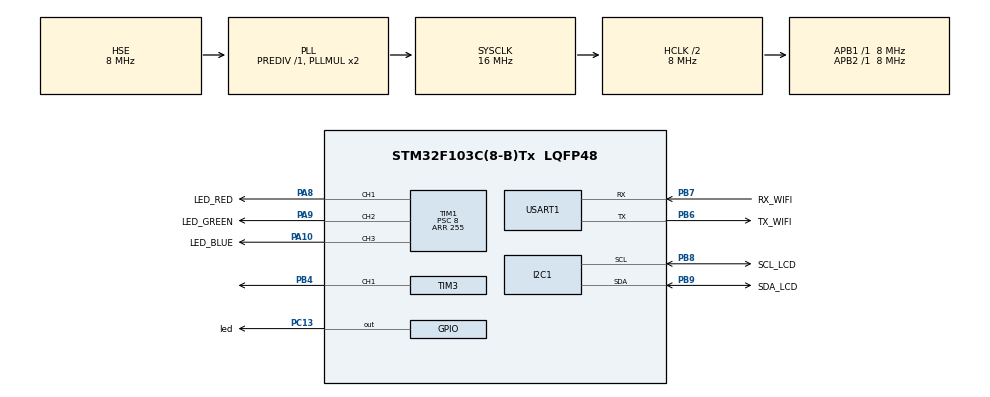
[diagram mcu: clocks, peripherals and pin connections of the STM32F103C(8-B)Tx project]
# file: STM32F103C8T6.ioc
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Mcu.Family=STM32F1
Mcu.Name=STM32F103C(8-B)Tx
Mcu.Package=LQFP48
NVIC.PriorityGroup=NVIC_PRIORITYGROUP_4
NVIC.TIM2_IRQn=true\:0\:0\:false\:false\:true\:true\:true
NVIC.USART1_IRQn=true\:0\:0\:false\:false\:true\:true\:true
PA10.GPIO_Label=LED_BLUE
PA10.Signal=S_TIM1_CH3
PA13.Mode=Serial_Wire
PA13.Signal=SYS_JTMS-SWDIO
PA14.Mode=Serial_Wire
PA14.Signal=SYS_JTCK-SWCLK
PA8.GPIO_Label=LED_RED
PA8.Signal=S_TIM1_CH1
PA9.GPIO_Label=LED_GREEN
PA9.Signal=S_TIM1_CH2
PB4.Signal=S_TIM3_CH1
PB6.GPIO_Label=TX_WIFI
PB6.Mode=Asynchronous
PB6.Signal=USART1_TX
PB7.GPIO_Label=RX_WIFI
PB7.Mode=Asynchronous
PB7.Signal=USART1_RX
PB8.GPIO_Label=SCL_LCD
PB8.Mode=I2C
PB8.Signal=I2C1_SCL
PB9.GPIO_Label=SDA_LCD
PB9.Mode=I2C
PB9.Signal=I2C1_SDA
PC13-TAMPER-RTC.GPIO_Label=led
PC13-TAMPER-RTC.Signal=GPIO_Output
PD0-OSC_IN.Mode=HSE-External-Oscillator
PD0-OSC_IN.Signal=RCC_OSC_IN
PD1-OSC_OUT.Mode=HSE-External-Oscillator
PD1-OSC_OUT.Signal=RCC_OSC_OUT
ProjectManager.HeapSize=0x200
ProjectManager.StackSize=0x400
ProjectManager.TargetToolchain=STM32CubeIDE
RCC.AHBCLKDivider=RCC_SYSCLK_DIV2
RCC.AHBFreq_Value=8000000
RCC.APB1Freq_Value=8000000
RCC.APB1TimFreq_Value=8000000
RCC.APB2Freq_Value=8000000
RCC.APB2TimFreq_Value=8000000
RCC.HCLKFreq_Value=8000000
RCC.PLLSourceVirtual=RCC_PLLSOURCE_HSE
RCC.SYSCLKFreq_VALUE=16000000
RCC.SYSCLKSource=RCC_SYSCLKSOURCE_PLLCLK
RCC.USBFreq_Value=16000000
SH.S_TIM1_CH1.0=TIM1_CH1,PWM Generation1 CH1
SH.S_TIM1_CH2.0=TIM1_CH2,PWM Generation2 CH2
SH.S_TIM1_CH3.0=TIM1_CH3,PWM Generation3 CH3
SH.S_TIM3_CH1.0=TIM3_CH1,PWM Generation1 CH1
TIM1.AutoReloadPreload=TIM_AUTORELOAD_PRELOAD_ENABLE
TIM1.Channel-PWM\ Generation1\ CH1=TIM_CHANNEL_1
TIM1.Channel-PWM\ Generation2\ CH2=TIM_CHANNEL_2
TIM1.Channel-PWM\ Generation3\ CH3=TIM_CHANNEL_3
TIM1.Period=255
TIM1.Prescaler=8
TIM2.Period=9
TIM2.Prescaler=7999
TIM3.Channel-PWM\ Generation1\ CH1=TIM_CHANNEL_1
TIM3.Period=1000
TIM3.Pulse-PWM\ Generation1\ CH1=500
USART1.VirtualMode=VM_ASYNC
VP_TIM1_VS_ClockSourceINT.Mode=Internal
VP_TIM2_VS_ClockSourceINT.Mode=Internal
VP_TIM3_VS_ClockSourceINT.Mode=Internal
board=custom

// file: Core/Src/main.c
/* USER CODE BEGIN Header */
/**
  ******************************************************************************
  * @file           : main.c
  * @brief          : Main program body
  ******************************************************************************
  * @attention
  *
  * <h2><center>&copy; Copyright (c) 2024 STMicroelectronics.
  * All rights reserved.</center></h2>
  *
  * This software component is licensed by ST under BSD 3-Clause license,
  * the "License"; You may not use this file except in compliance with the
  * License. You may obtain a copy of the License at:
  *                        opensource.org/licenses/BSD-3-Clause
  *
  ******************************************************************************
  */
/* USER CODE END Header */
#include "main.h"

/* USER CODE BEGIN Includes */
#include "signal.h"
/* USER CODE END Includes */

I2C_HandleTypeDef hi2c1;

TIM_HandleTypeDef htim1;
TIM_HandleTypeDef htim2;
TIM_HandleTypeDef htim3;

UART_HandleTypeDef huart1;

void SystemClock_Config(void);
static void MX_TIM2_Init(void);
static void MX_GPIO_Init(void);
static void MX_I2C1_Init(void);
static void MX_TIM1_Init(void);
static void MX_USART1_UART_Init(void);
static void MX_TIM3_Init(void);

int main(void)
{

  /* MCU Configuration--------------------------------------------------------*/

  /* Reset of all peripherals, Initializes the Flash interface and the Systick. */
  HAL_Init();

  /* Configure the system clock */
  SystemClock_Config();

  /* Initialize all configured peripherals */
  MX_TIM2_Init();
  MX_GPIO_Init();
  MX_I2C1_Init();
  MX_TIM1_Init();
  MX_USART1_UART_Init();
  MX_TIM3_Init();
  /* USER CODE BEGIN 2 */
  lcd_init();
  HAL_TIM_Base_Start_IT(&htim2);
  HAL_UART_Receive_IT (&huart1 , Rx_data , 1);
//  HAL_UART_Receive_IT(&huart1 , &temp , 1);
  /* USER CODE END 2 */

  /* Infinite loop */
  /* USER CODE BEGIN WHILE */
  SCH_Add_Task(fsm_run, 0, 1);
  while (1)
  {
	  SCH_Dispatch_Tasks();

    /* USER CODE END WHILE */

  }
}

void SystemClock_Config(void)
{
  RCC_OscInitTypeDef RCC_OscInitStruct = {0};
  RCC_ClkInitTypeDef RCC_ClkInitStruct = {0};

  /** Initializes the RCC Oscillators according to the specified parameters
  * in the RCC_OscInitTypeDef structure.
  */
  RCC_OscInitStruct.OscillatorType = RCC_OSCILLATORTYPE_HSE;
  RCC_OscInitStruct.HSEState = RCC_HSE_ON;
  RCC_OscInitStruct.HSEPredivValue = RCC_HSE_PREDIV_DIV1;
  RCC_OscInitStruct.HSIState = RCC_HSI_ON;
  RCC_OscInitStruct.PLL.PLLState = RCC_PLL_ON;
  RCC_OscInitStruct.PLL.PLLSource = RCC_PLLSOURCE_HSE;
  RCC_OscInitStruct.PLL.PLLMUL = RCC_PLL_MUL2;
  if (HAL_RCC_OscConfig(&RCC_OscInitStruct) != HAL_OK)
  {
    Error_Handler();
  }
  /** Initializes the CPU, AHB and APB buses clocks
  */
  RCC_ClkInitStruct.ClockType = RCC_CLOCKTYPE_HCLK|RCC_CLOCKTYPE_SYSCLK
                              |RCC_CLOCKTYPE_PCLK1|RCC_CLOCKTYPE_PCLK2;
  RCC_ClkInitStruct.SYSCLKSource = RCC_SYSCLKSOURCE_PLLCLK;
  RCC_ClkInitStruct.AHBCLKDivider = RCC_SYSCLK_DIV2;
  RCC_ClkInitStruct.APB1CLKDivider = RCC_HCLK_DIV1;
  RCC_ClkInitStruct.APB2CLKDivider = RCC_HCLK_DIV1;

  if (HAL_RCC_ClockConfig(&RCC_ClkInitStruct, FLASH_LATENCY_0) != HAL_OK)
  {
    Error_Handler();
  }
}

static void MX_I2C1_Init(void)
{

  hi2c1.Instance = I2C1;
  hi2c1.Init.ClockSpeed = 100000;
  hi2c1.Init.DutyCycle = I2C_DUTYCYCLE_2;
  hi2c1.Init.OwnAddress1 = 0;
  hi2c1.Init.AddressingMode = I2C_ADDRESSINGMODE_7BIT;
  hi2c1.Init.DualAddressMode = I2C_DUALADDRESS_DISABLE;
  hi2c1.Init.OwnAddress2 = 0;
  hi2c1.Init.GeneralCallMode = I2C_GENERALCALL_DISABLE;
  hi2c1.Init.NoStretchMode = I2C_NOSTRETCH_DISABLE;
  if (HAL_I2C_Init(&hi2c1) != HAL_OK)
  {
    Error_Handler();
  }

}

static void MX_TIM1_Init(void)
{

  TIM_ClockConfigTypeDef sClockSourceConfig = {0};
  TIM_MasterConfigTypeDef sMasterConfig = {0};
  TIM_OC_InitTypeDef sConfigOC = {0};
  TIM_BreakDeadTimeConfigTypeDef sBreakDeadTimeConfig = {0};

  htim1.Instance = TIM1;
  htim1.Init.Prescaler = 8;
  htim1.Init.CounterMode = TIM_COUNTERMODE_UP;
  htim1.Init.Period = 255;
  htim1.Init.ClockDivision = TIM_CLOCKDIVISION_DIV1;
  htim1.Init.RepetitionCounter = 0;
  htim1.Init.AutoReloadPreload = TIM_AUTORELOAD_PRELOAD_ENABLE;
  if (HAL_TIM_Base_Init(&htim1) != HAL_OK)
  {
    Error_Handler();
  }
  sClockSourceConfig.ClockSource = TIM_CLOCKSOURCE_INTERNAL;
  if (HAL_TIM_ConfigClockSource(&htim1, &sClockSourceConfig) != HAL_OK)
  {
    Error_Handler();
  }
  if (HAL_TIM_PWM_Init(&htim1) != HAL_OK)
  {
    Error_Handler();
  }
  sMasterConfig.MasterOutputTrigger = TIM_TRGO_RESET;
  sMasterConfig.MasterSlaveMode = TIM_MASTERSLAVEMODE_DISABLE;
  if (HAL_TIMEx_MasterConfigSynchronization(&htim1, &sMasterConfig) != HAL_OK)
  {
    Error_Handler();
  }
  sConfigOC.OCMode = TIM_OCMODE_PWM1;
  sConfigOC.Pulse = 0;
  sConfigOC.OCPolarity = TIM_OCPOLARITY_HIGH;
  sConfigOC.OCNPolarity = TIM_OCNPOLARITY_HIGH;
  sConfigOC.OCFastMode = TIM_OCFAST_DISABLE;
  sConfigOC.OCIdleState = TIM_OCIDLESTATE_RESET;
  sConfigOC.OCNIdleState = TIM_OCNIDLESTATE_RESET;
  if (HAL_TIM_PWM_ConfigChannel(&htim1, &sConfigOC, TIM_CHANNEL_1) != HAL_OK)
  {
    Error_Handler();
  }
  if (HAL_TIM_PWM_ConfigChannel(&htim1, &sConfigOC, TIM_CHANNEL_2) != HAL_OK)
  {
    Error_Handler();
  }
  if (HAL_TIM_PWM_ConfigChannel(&htim1, &sConfigOC, TIM_CHANNEL_3) != HAL_OK)
  {
    Error_Handler();
  }
  sBreakDeadTimeConfig.OffStateRunMode = TIM_OSSR_DISABLE;
  sBreakDeadTimeConfig.OffStateIDLEMode = TIM_OSSI_DISABLE;
  sBreakDeadTimeConfig.LockLevel = TIM_LOCKLEVEL_OFF;
  sBreakDeadTimeConfig.DeadTime = 0;
  sBreakDeadTimeConfig.BreakState = TIM_BREAK_DISABLE;
  sBreakDeadTimeConfig.BreakPolarity = TIM_BREAKPOLARITY_HIGH;
  sBreakDeadTimeConfig.AutomaticOutput = TIM_AUTOMATICOUTPUT_DISABLE;
  if (HAL_TIMEx_ConfigBreakDeadTime(&htim1, &sBreakDeadTimeConfig) != HAL_OK)
  {
    Error_Handler();
  }
  HAL_TIM_MspPostInit(&htim1);

}

static void MX_TIM2_Init(void)
{

  TIM_ClockConfigTypeDef sClockSourceConfig = {0};
  TIM_MasterConfigTypeDef sMasterConfig = {0};

  htim2.Instance = TIM2;
  htim2.Init.Prescaler = 7999;
  htim2.Init.CounterMode = TIM_COUNTERMODE_UP;
  htim2.Init.Period = 9;
  htim2.Init.ClockDivision = TIM_CLOCKDIVISION_DIV1;
  htim2.Init.AutoReloadPreload = TIM_AUTORELOAD_PRELOAD_DISABLE;
  if (HAL_TIM_Base_Init(&htim2) != HAL_OK)
  {
    Error_Handler();
  }
  sClockSourceConfig.ClockSource = TIM_CLOCKSOURCE_INTERNAL;
  if (HAL_TIM_ConfigClockSource(&htim2, &sClockSourceConfig) != HAL_OK)
  {
    Error_Handler();
  }
  sMasterConfig.MasterOutputTrigger = TIM_TRGO_RESET;
  sMasterConfig.MasterSlaveMode = TIM_MASTERSLAVEMODE_DISABLE;
  if (HAL_TIMEx_MasterConfigSynchronization(&htim2, &sMasterConfig) != HAL_OK)
  {
    Error_Handler();
  }

}

static void MX_TIM3_Init(void)
{

  TIM_ClockConfigTypeDef sClockSourceConfig = {0};
  TIM_MasterConfigTypeDef sMasterConfig = {0};
  TIM_OC_InitTypeDef sConfigOC = {0};

  htim3.Instance = TIM3;
  htim3.Init.Prescaler = 0;
  htim3.Init.CounterMode = TIM_COUNTERMODE_UP;
  htim3.Init.Period = 1000;
  htim3.Init.ClockDivision = TIM_CLOCKDIVISION_DIV1;
  htim3.Init.AutoReloadPreload = TIM_AUTORELOAD_PRELOAD_DISABLE;
  if (HAL_TIM_Base_Init(&htim3) != HAL_OK)
  {
    Error_Handler();
  }
  sClockSourceConfig.ClockSource = TIM_CLOCKSOURCE_INTERNAL;
  if (HAL_TIM_ConfigClockSource(&htim3, &sClockSourceConfig) != HAL_OK)
  {
    Error_Handler();
  }
  if (HAL_TIM_PWM_Init(&htim3) != HAL_OK)
  {
    Error_Handler();
  }
  sMasterConfig.MasterOutputTrigger = TIM_TRGO_RESET;
  sMasterConfig.MasterSlaveMode = TIM_MASTERSLAVEMODE_DISABLE;
  if (HAL_TIMEx_MasterConfigSynchronization(&htim3, &sMasterConfig) != HAL_OK)
  {
    Error_Handler();
  }
  sConfigOC.OCMode = TIM_OCMODE_PWM1;
  sConfigOC.Pulse = 500;
  sConfigOC.OCPolarity = TIM_OCPOLARITY_HIGH;
  sConfigOC.OCFastMode = TIM_OCFAST_DISABLE;
  if (HAL_TIM_PWM_ConfigChannel(&htim3, &sConfigOC, TIM_CHANNEL_1) != HAL_OK)
  {
    Error_Handler();
  }
  HAL_TIM_MspPostInit(&htim3);

}

static void MX_USART1_UART_Init(void)
{

  huart1.Instance = USART1;
  huart1.Init.BaudRate = 115200;
  huart1.Init.WordLength = UART_WORDLENGTH_8B;
  huart1.Init.StopBits = UART_STOPBITS_1;
  huart1.Init.Parity = UART_PARITY_NONE;
  huart1.Init.Mode = UART_MODE_TX_RX;
  huart1.Init.HwFlowCtl = UART_HWCONTROL_NONE;
  huart1.Init.OverSampling = UART_OVERSAMPLING_16;
  if (HAL_UART_Init(&huart1) != HAL_OK)
  {
    Error_Handler();
  }

}

static void MX_GPIO_Init(void)
{
  GPIO_InitTypeDef GPIO_InitStruct = {0};

  /* GPIO Ports Clock Enable */
  __HAL_RCC_GPIOC_CLK_ENABLE();
  __HAL_RCC_GPIOD_CLK_ENABLE();
  __HAL_RCC_GPIOA_CLK_ENABLE();
  __HAL_RCC_GPIOB_CLK_ENABLE();

  /*Configure GPIO pin Output Level */
  HAL_GPIO_WritePin(led_GPIO_Port, led_Pin, GPIO_PIN_RESET);

  /*Configure GPIO pin : led_Pin */
  GPIO_InitStruct.Pin = led_Pin;
  GPIO_InitStruct.Mode = GPIO_MODE_OUTPUT_PP;
  GPIO_InitStruct.Pull = GPIO_NOPULL;
  GPIO_InitStruct.Speed = GPIO_SPEED_FREQ_LOW;
  HAL_GPIO_Init(led_GPIO_Port, &GPIO_InitStruct);

}

/* USER CODE BEGIN 4 */
void HAL_TIM_PeriodElapsedCallback(TIM_HandleTypeDef *htim)
{
	if(htim->Instance == TIM2)
	{
		SCH_Update();
	}
}
/* USER CODE END 4 */

void Error_Handler(void)
{
  __disable_irq();
  while (1)
  {
  }
}

/************************ (C) COPYRIGHT STMicroelectronics *****END OF FILE****/
